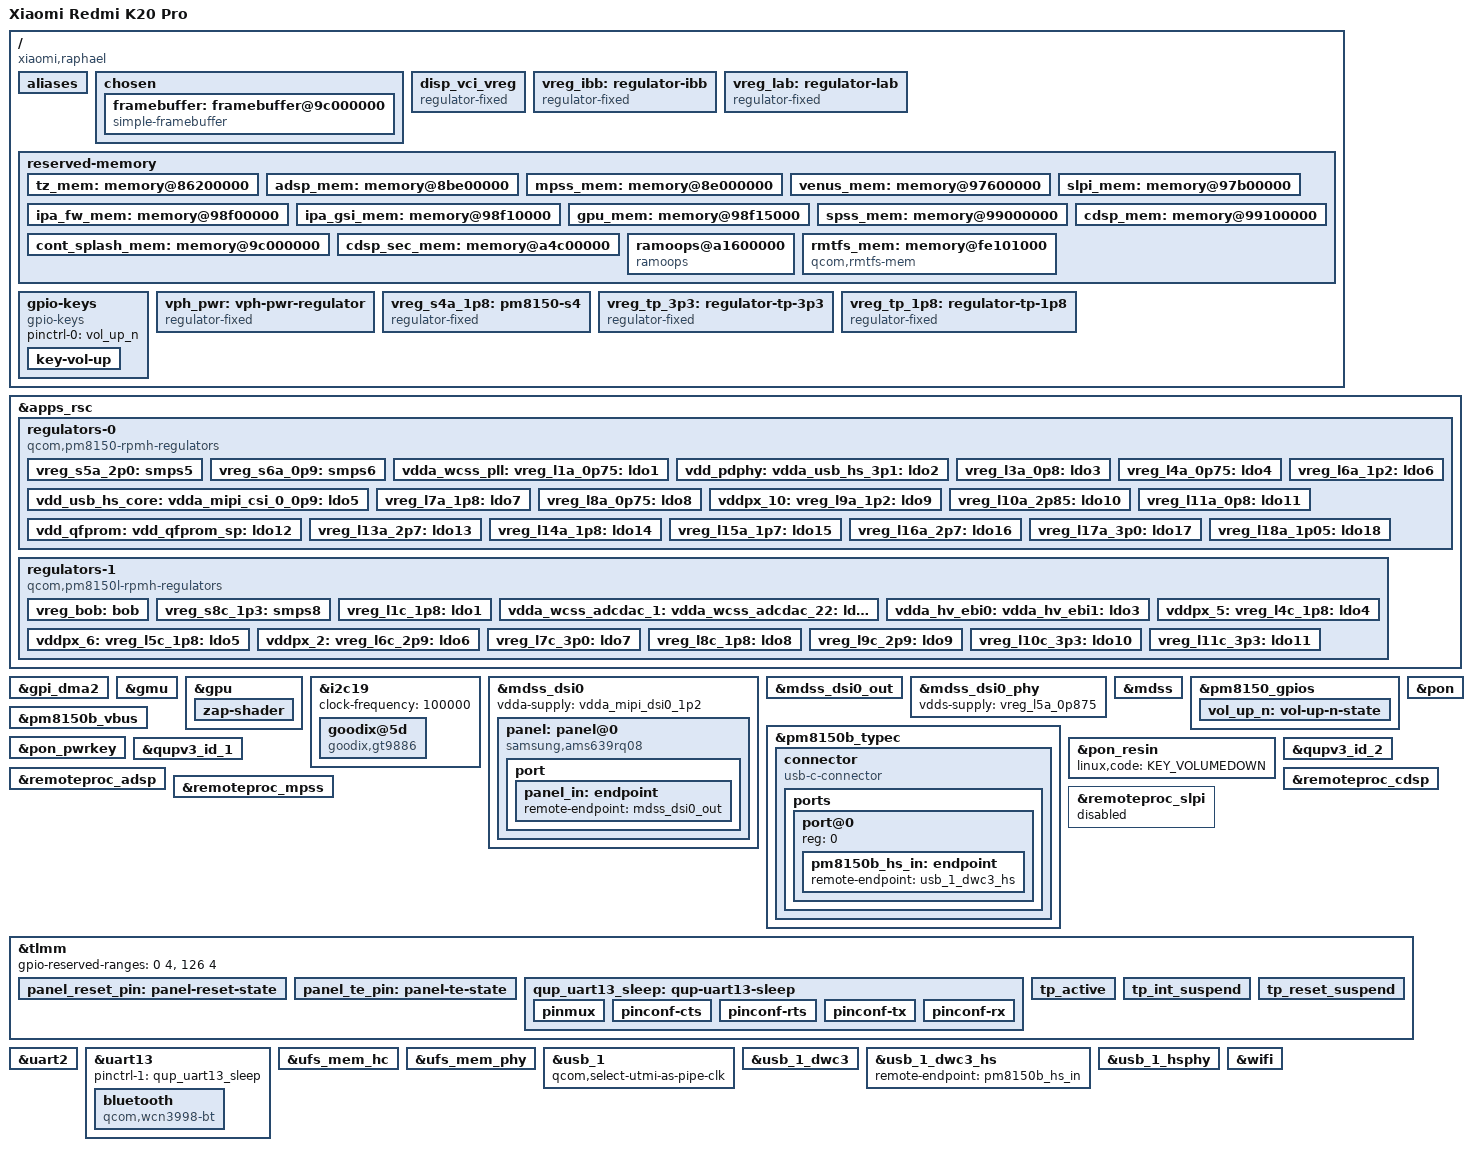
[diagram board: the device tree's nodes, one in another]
// SPDX-License-Identifier: BSD-3-Clause
/*
 * Copyright (c) 2025, Piyush Raj Chouhan <piyushchouhan1598@gmail.com>.
 */

/dts-v1/;

#include <dt-bindings/arm/qcom,ids.h>
#include <dt-bindings/pinctrl/qcom,pmic-gpio.h>
#include <dt-bindings/regulator/qcom,rpmh-regulator.h>
#include <dt-bindings/gpio/gpio.h>
#include <dt-bindings/usb/pd.h>
#include "sm8150.dtsi"
#include "pm8150.dtsi"
#include "pm8150b.dtsi"
#include "pm8150l.dtsi"

/* 
 * Rewrite reserved memory maps inherited from sm8150.dtsi to match the ones
 * used on xiaomi-raphael.
 * Note: this list is ordered by its memory address in sm8150.dtsi.
 */
/delete-node/ &tz_mem;      /* same address but larger, no place for rmtfs_mem! */
/delete-node/ &rmtfs_mem;   /* moved to completely different address */
/delete-node/ &adsp_mem;    /* same start address, but larger size */
/delete-node/ &mpss_mem;    /* same size, shifted higher, due to larger adsp_mem */
/delete-node/ &venus_mem;   /* same size, shifted higher */
/delete-node/ &slpi_mem;    /* same size, shifted higher */
/delete-node/ &ipa_fw_mem;  /* same size, shifted higher */
/delete-node/ &ipa_gsi_mem; /* same size, shifted higher */
/delete-node/ &gpu_mem;     /* same size, shifted higher */
/delete-node/ &spss_mem;    /* same size, shifted higher */
/delete-node/ &cdsp_mem;    /* same size, shifted higher */

/ {
	model = "Xiaomi Redmi K20 Pro";
	compatible = "xiaomi,raphael", "qcom,sm8150";
	qcom,msm-id = <QCOM_ID_SM8150 0x20000>; /* SM8150 v2 */
	qcom,board-id = <40 0>;
	chassis-type = "handset";

	aliases {
		bluetooth0 = &bluetooth;
		serial0 = &uart2;
		hsuart0 = &uart13;
		wifi0 = &wifi;
	};

	chosen {
		#address-cells = <2>;
		#size-cells = <2>;
		ranges;

		stdout-path = "serial0:115200n8";
		bootargs = "earlycon console=ttyMSM0,115200";

		framebuffer: framebuffer@9c000000 {
			compatible = "simple-framebuffer";
			reg = <0 0x9c000000 0 (1080 * 2340 * 4)>;
			width = <1080>;
			height = <2340>;
			stride = <(1080 * 4)>;
			format = "a8r8g8b8";
			display = <&panel>;
			clocks = <&gcc GCC_DISP_HF_AXI_CLK>;
		};
	};

	disp_vci_vreg: disp_vci_vreg {
		compatible = "regulator-fixed";
		regulator-name = "disp_vci_vreg";
		enable-active-high;
		regulator-boot-on;
		gpio = <&tlmm 99 GPIO_ACTIVE_HIGH>;
	};

	vreg_ibb: regulator-ibb {
		compatible = "regulator-fixed";
		regulator-name = "ibb";
		regulator-min-microvolt = <6000000>;
		regulator-max-microvolt = <6000000>;
	};

	vreg_lab: regulator-lab {
		compatible = "regulator-fixed";
		regulator-name = "lab";
		regulator-min-microvolt = <6000000>;
		regulator-max-microvolt = <6000000>;
	};

	reserved-memory {
		tz_mem: memory@86200000 {
			no-map;
			reg = <0x0 0x86200000 0x0 0x5500000>;
		};

		adsp_mem: memory@8be00000 {
			no-map;
			reg = <0x0 0x8be00000 0x0 0x2200000>;
		};

		mpss_mem: memory@8e000000 {
			no-map;
			reg = <0x0 0x8e000000 0x0 0x9600000>;
		};

		venus_mem: memory@97600000 {
			no-map;
			reg = <0x0 0x97600000 0x0 0x500000>;
		};

		slpi_mem: memory@97b00000 {
			no-map;
			reg = <0x0 0x97b00000 0x0 0x1400000>;
		};

		ipa_fw_mem: memory@98f00000 {
			no-map;
			reg = <0x0 0x98f00000 0x0 0x10000>;
		};

		ipa_gsi_mem: memory@98f10000 {
			no-map;
			reg = <0x0 0x98f10000 0x0 0x5000>;
		};

		gpu_mem: memory@98f15000 {
			no-map;
			reg = <0x0 0x98f15000 0x0 0x2000>;
		};

		spss_mem: memory@99000000 {
			no-map;
			reg = <0x0 0x99000000 0x0 0x100000>;
		};

		cdsp_mem: memory@99100000 {
			no-map;
			reg = <0x0 0x99100000 0x0 0x1400000>;
		};

		cont_splash_mem: memory@9c000000 {
			reg = <0x0 0x9c000000 0x0 0x2400000>;
			no-map;
		};

		cdsp_sec_mem: memory@a4c00000 {
			reg = <0x0 0xa4c00000 0x0 0x3c00000>;
			no-map;
		};
		
		ramoops@a1600000 {
			compatible = "ramoops";
			reg = <0x0 0xa1600000 0x0 0x800000>;
			console-size = <0x400000>;
			ecc-size = <0>;
			ftrace-size = <0>;
			pmsg-size = <0x200000>;
			record-size = <0>;
			no-map;
		};

		rmtfs_mem: memory@fe101000 {
			compatible = "qcom,rmtfs-mem";
			reg = <0 0xfe101000 0 0x300000>;
			no-map;

			qcom,client-id = <1>;
			qcom,vmid = <15>;
		};
	};

	gpio-keys {
		compatible = "gpio-keys";

		pinctrl-names = "default";
		pinctrl-0 = <&vol_up_n>;

		key-vol-up {
			label = "Volume Up";
			linux,code = <KEY_VOLUMEUP>;
			gpios = <&pm8150_gpios 6 GPIO_ACTIVE_LOW>;
		};
	};

	vph_pwr: vph-pwr-regulator {
		compatible = "regulator-fixed";
		regulator-name = "vph_pwr";
		regulator-min-microvolt = <3700000>;
		regulator-max-microvolt = <3700000>;
	};

	/*
	 * Apparently RPMh does not provide support for PM8150 S4 because it
	 * is always-on; model it as a fixed regulator.
	 */
	vreg_s4a_1p8: pm8150-s4 {
		compatible = "regulator-fixed";
		regulator-name = "vreg_s4a_1p8";

		regulator-min-microvolt = <1800000>;
		regulator-max-microvolt = <1800000>;

		regulator-always-on;
		regulator-boot-on;

		vin-supply = <&vph_pwr>;
	};

	vreg_tp_3p3: regulator-tp-3p3 {
		compatible = "regulator-fixed";
		regulator-name = "vreg_tp_3p3";
		regulator-min-microvolt = <3300000>;
		regulator-max-microvolt = <3300000>;
		gpio = <&tlmm 98 GPIO_ACTIVE_HIGH>;
		enable-active-high;
		regulator-boot-on;
		startup-delay-us = <5000>;
	};
	
	vreg_tp_1p8: regulator-tp-1p8 {
		compatible = "regulator-fixed";
		regulator-name = "vreg_tp_1p8";
		regulator-min-microvolt = <1800000>;
		regulator-max-microvolt = <1800000>;
		gpio = <&tlmm 100 GPIO_ACTIVE_HIGH>;
		enable-active-high;
		regulator-boot-on;
		startup-delay-us = <5000>;
	};
};

&apps_rsc {
	regulators-0 {
		compatible = "qcom,pm8150-rpmh-regulators";
		qcom,pmic-id = "a";

		vdd-s1-supply = <&vph_pwr>;
		vdd-s2-supply = <&vph_pwr>;
		vdd-s3-supply = <&vph_pwr>;
		vdd-s4-supply = <&vph_pwr>;
		vdd-s5-supply = <&vph_pwr>;
		vdd-s6-supply = <&vph_pwr>;
		vdd-s7-supply = <&vph_pwr>;
		vdd-s8-supply = <&vph_pwr>;
		vdd-s9-supply = <&vph_pwr>;
		vdd-s10-supply = <&vph_pwr>;

		vdd-l1-l8-l11-supply = <&vreg_s6a_0p9>;
		vdd-l2-l10-supply = <&vreg_bob>;
		vdd-l3-l4-l5-l18-supply = <&vreg_s6a_0p9>;
		vdd-l6-l9-supply = <&vreg_s8c_1p3>;
		vdd-l7-l12-l14-l15-supply = <&vreg_s5a_2p0>;
		vdd-l13-l16-l17-supply = <&vreg_bob>;

		vreg_s5a_2p0: smps5 {
			regulator-min-microvolt = <1904000>;
			regulator-max-microvolt = <2000000>;
		};

		vreg_s6a_0p9: smps6 {
			regulator-min-microvolt = <920000>;
			regulator-max-microvolt = <1128000>;
		};

		vdda_wcss_pll:
		vreg_l1a_0p75: ldo1 {
			regulator-min-microvolt = <752000>;
			regulator-max-microvolt = <752000>;
			regulator-initial-mode = <RPMH_REGULATOR_MODE_HPM>;
		};

		vdd_pdphy:
		vdda_usb_hs_3p1:
		vreg_l2a_3p1: ldo2 {
			regulator-min-microvolt = <3072000>;
			regulator-max-microvolt = <3072000>;
			regulator-initial-mode = <RPMH_REGULATOR_MODE_HPM>;
		};

		vreg_l3a_0p8: ldo3 {
			regulator-min-microvolt = <480000>;
			regulator-max-microvolt = <932000>;
			regulator-initial-mode = <RPMH_REGULATOR_MODE_HPM>;
		};

		/* L4A supplies VDD_LPI_MX_* (VDD_LPI_MX_A_1). Board label: vreg_l4a_0p75.
		* PM8150 device spec: L4A nominal = 0.816 V, active min = 0.752 V, active max = 0.904 V,
		* IRATED = 300 mA. If the board programs L4A to ~0.752 V, keep min=752000 and max=816000.
		*/
		vreg_l4a_0p75: ldo4 {
			regulator-min-microvolt = <752000>;
			regulator-max-microvolt = <816000>;
			regulator-initial-mode = <RPMH_REGULATOR_MODE_HPM>;
		};

		vdd_usb_hs_core:
		vdda_mipi_csi_0_0p9:
		vdda_mipi_csi_1_0p9:
		vdda_mipi_csi_2_0p9:
		vdda_mipi_csi_3_0p9:
		vdda_mipi_dsi_0_0p9:
		vdda_mipi_dsi_1_0p9:
		vdda_mipi_dsi_0_pll_0p9:
		vdda_mipi_dsi_1_pll_0p9:
		vdda_pcie_1ln_core:
		vdda_pcie_2ln_core:
		vdda_pll_hv_cc_ebi01:
		vdda_pll_hv_cc_ebi23:
		vdda_qrefs_0p875_5:
		vdda_sp_sensor:
		vdda_ufs_2ln_core_1:
		vdda_ufs_2ln_core_2:
		vdda_qlink_lv:
		vdda_qlink_lv_ck:
		vreg_l5a_0p875: ldo5 {
			regulator-min-microvolt = <880000>;
			regulator-max-microvolt = <880000>;
			regulator-initial-mode = <RPMH_REGULATOR_MODE_HPM>;
		};

		vreg_l6a_1p2: ldo6 {
			regulator-min-microvolt = <1200000>;
			regulator-max-microvolt = <1200000>;
			regulator-initial-mode = <RPMH_REGULATOR_MODE_HPM>;
		};

		vreg_l7a_1p8: ldo7 {
			regulator-min-microvolt = <1800000>;
			regulator-max-microvolt = <1800000>;
			regulator-initial-mode = <RPMH_REGULATOR_MODE_HPM>;
		};

		/* PM8150 LDO8 (L8A) — supplies vreg_l8a_0p75
		* Device spec: nominal 0.752 V, active min 0.752 V, active max 0.904 V, IRATED = 300 mA
		*/
		vreg_l8a_0p75: ldo8 {
                        regulator-min-microvolt = <752000>;                              
                        regulator-max-microvolt = <816000>;
		};

		vddpx_10:
		vreg_l9a_1p2: ldo9 {
			regulator-min-microvolt = <1200000>;
			regulator-max-microvolt = <1200000>;
			regulator-initial-mode = <RPMH_REGULATOR_MODE_HPM>;
		};

		vreg_l10a_2p85: ldo10 {
			regulator-min-microvolt = <2850000>;
			regulator-max-microvolt = <2960000>;
			regulator-initial-mode = <RPMH_REGULATOR_MODE_HPM>;
		};

		vreg_l11a_0p8: ldo11 {
			regulator-min-microvolt = <800000>;
			regulator-max-microvolt = <800000>;
			regulator-initial-mode = <RPMH_REGULATOR_MODE_HPM>;
		};

		vdd_qfprom:
		vdd_qfprom_sp:
		vdda_apc_cs_1p8:
		vdda_gfx_cs_1p8:
		vdda_usb_hs_1p8:
		vdda_qrefs_vref_1p8:
		vddpx_10_a:
		vreg_l12a_1p8: ldo12 {
			regulator-min-microvolt = <1800000>;
			regulator-max-microvolt = <1800000>;
			regulator-initial-mode = <RPMH_REGULATOR_MODE_HPM>;
		};

		vreg_l13a_2p7: ldo13 {
			regulator-min-microvolt = <2704000>;
			regulator-max-microvolt = <2704000>;
			regulator-initial-mode = <RPMH_REGULATOR_MODE_HPM>;
		};

		vreg_l14a_1p8: ldo14 {
			regulator-min-microvolt = <1800000>;
			regulator-max-microvolt = <1880000>;
			regulator-initial-mode = <RPMH_REGULATOR_MODE_HPM>;
		};

		vreg_l15a_1p7: ldo15 {
			regulator-min-microvolt = <1704000>;
			regulator-max-microvolt = <1704000>;
			regulator-initial-mode = <RPMH_REGULATOR_MODE_HPM>;
		};

		vreg_l16a_2p7: ldo16 {
			regulator-min-microvolt = <2704000>;
			regulator-max-microvolt = <2960000>;
			regulator-initial-mode = <RPMH_REGULATOR_MODE_HPM>;
		};

		vreg_l17a_3p0: ldo17 {
			regulator-min-microvolt = <2856000>;
			regulator-max-microvolt = <3008000>;
			regulator-initial-mode = <RPMH_REGULATOR_MODE_HPM>;
		};

		vreg_l18a_1p05: ldo18 {
			regulator-min-microvolt = <800000>;
			regulator-max-microvolt = <800000>;
			regulator-initial-mode = <RPMH_REGULATOR_MODE_HPM>;
		};
	};

	regulators-1 {
		compatible = "qcom,pm8150l-rpmh-regulators";
		qcom,pmic-id = "c";

		vdd-s1-supply = <&vph_pwr>;
		vdd-s2-supply = <&vph_pwr>;
		vdd-s3-supply = <&vph_pwr>;
		vdd-s4-supply = <&vph_pwr>;
		vdd-s5-supply = <&vph_pwr>;
		vdd-s6-supply = <&vph_pwr>;
		vdd-s7-supply = <&vph_pwr>;
		vdd-s8-supply = <&vph_pwr>;

		vdd-l1-l8-supply = <&vreg_s4a_1p8>;
		vdd-l2-l3-supply = <&vreg_s8c_1p3>;
		vdd-l4-l5-l6-supply = <&vreg_bob>;
		vdd-l7-l11-supply = <&vreg_bob>;
		vdd-l9-l10-supply = <&vreg_bob>;

		vdd-bob-supply = <&vph_pwr>;
		vdd-flash-supply = <&vreg_bob>;
		vdd-rgb-supply = <&vreg_bob>;

		vreg_bob: bob {
			regulator-min-microvolt = <3008000>;
			regulator-max-microvolt = <4000000>;
			regulator-initial-mode = <RPMH_REGULATOR_MODE_AUTO>;
			regulator-allow-bypass;
		};

		vreg_s8c_1p3: smps8 {
			regulator-min-microvolt = <1352000>;
			regulator-max-microvolt = <1352000>;
		};

		vreg_l1c_1p8: ldo1 {
			regulator-min-microvolt = <1800000>;
			regulator-max-microvolt = <1800000>;
			regulator-initial-mode = <RPMH_REGULATOR_MODE_HPM>;
		};

		vdda_wcss_adcdac_1:
		vdda_wcss_adcdac_22:
		vreg_l2c_1p3: ldo2 {
			regulator-min-microvolt = <1304000>;
			regulator-max-microvolt = <1304000>;
			regulator-initial-mode = <RPMH_REGULATOR_MODE_HPM>;
		};

		vdda_hv_ebi0:
		vdda_hv_ebi1:
		vdda_hv_ebi2:
		vdda_hv_ebi3:
		vdda_hv_refgen0:
		vdda_mipi_dsi0_1p2:
		vdda_qlink_hv_ck:
		vreg_l3c_1p2: ldo3 {
			regulator-min-microvolt = <1200000>;
			regulator-max-microvolt = <1200000>;
			regulator-initial-mode = <RPMH_REGULATOR_MODE_HPM>;
		};

		vddpx_5:
		vreg_l4c_1p8: ldo4 {
			regulator-min-microvolt = <1704000>;
			regulator-max-microvolt = <2928000>;
			regulator-initial-mode = <RPMH_REGULATOR_MODE_HPM>;
		};

		vddpx_6:
		vreg_l5c_1p8: ldo5 {
			regulator-min-microvolt = <1704000>;
			regulator-max-microvolt = <2928000>;
			regulator-initial-mode = <RPMH_REGULATOR_MODE_HPM>;
		};

		vddpx_2:
		vreg_l6c_2p9: ldo6 {
			regulator-min-microvolt = <1800000>;
			regulator-max-microvolt = <2960000>;
			regulator-initial-mode = <RPMH_REGULATOR_MODE_HPM>;
		};

		vreg_l7c_3p0: ldo7 {
			regulator-min-microvolt = <2856000>;
			regulator-max-microvolt = <3104000>;
			regulator-initial-mode = <RPMH_REGULATOR_MODE_HPM>;
		};

		vreg_l8c_1p8: ldo8 {
			regulator-min-microvolt = <1800000>;
			regulator-max-microvolt = <1800000>;
			regulator-initial-mode = <RPMH_REGULATOR_MODE_HPM>;
		};

		vreg_l9c_2p9: ldo9 {
			regulator-min-microvolt = <2704000>;
			regulator-max-microvolt = <2960000>;
			regulator-initial-mode = <RPMH_REGULATOR_MODE_HPM>;
		};

		vreg_l10c_3p3: ldo10 {
			regulator-min-microvolt = <3000000>;
			regulator-max-microvolt = <3312000>;
			regulator-initial-mode = <RPMH_REGULATOR_MODE_HPM>;
		};

		vreg_l11c_3p3: ldo11 {
			regulator-min-microvolt = <3000000>;
			regulator-max-microvolt = <3312000>;
			regulator-initial-mode = <RPMH_REGULATOR_MODE_HPM>;
		};
	};
};

&gpi_dma2 {
	status = "okay";
};

&gmu {
	status = "okay";
};

&gpu {
	status = "okay";
	
	zap-shader {
		memory-region = <&gpu_mem>;
		firmware-name = "qcom/sm8150/Xiaomi/raphael/a640_zap.mbn";
	};
};

&i2c19 {
	clock-frequency = <100000>;
	status = "okay";
	goodix@5d {
		compatible = "goodix,gt9886";
		reg = <0x5d>;
		avdd-supply = <&vreg_tp_3p3>;
		vddio-supply = <&vreg_tp_1p8>;
		interrupts-extended = <&tlmm 122 IRQ_TYPE_LEVEL_LOW>;
		reset-gpios = <&tlmm 54 GPIO_ACTIVE_LOW>;
		touchscreen-size-x = <1080>;
		touchscreen-size-y = <2340>;
	};
};

&mdss_dsi0 {
	vdda-supply = <&vdda_mipi_dsi0_1p2>;
	status = "okay";
	panel:	panel@0 {
		compatible = "samsung,ams639rq08";
		reg = <0>;
		status = "okay";
		
		vddio-supply = <&vreg_l14a_1p8>;
		vdd3p3-supply = <&disp_vci_vreg>;

		vsn-supply = <&vreg_ibb>;
		vsp-supply = <&vreg_lab>;

		reset-gpios = <&tlmm 6 GPIO_ACTIVE_LOW>;
		
		pinctrl-names = "default", "sleep";
		pinctrl-0 = <&panel_reset_pin &panel_te_pin>;

		port {
			panel_in: endpoint {
				remote-endpoint = <&mdss_dsi0_out>;
			};
		};
	};
};

&mdss_dsi0_out {
	data-lanes = <0 1 2 3>;
	remote-endpoint = <&panel_in>;
};

&mdss_dsi0_phy {
	status = "okay";
	vdds-supply = <&vreg_l5a_0p875>;
};

&mdss {
	status = "okay";
};

&pm8150_gpios {
	vol_up_n: vol-up-n-state {
		pins = "gpio6";
		function = PMIC_GPIO_FUNC_NORMAL;
		input-enable;
		bias-pull-up;
	};
};

&pm8150b_typec {
	vdd-vbus-supply = <&pm8150b_vbus>;
	vdd-pdphy-supply = <&vdda_usb_hs_3p1>;
	status = "okay";

	connector {
		compatible = "usb-c-connector";

		power-role = "source";
		data-role = "dual";
		self-powered;

		source-pdos = <PDO_FIXED(5000, 3000, PDO_FIXED_DUAL_ROLE |
			       PDO_FIXED_USB_COMM | PDO_FIXED_DATA_SWAP)>;

		ports {
			#address-cells = <1>;
			#size-cells = <0>;

			port@0 {
				reg = <0>;
				pm8150b_hs_in: endpoint {
					remote-endpoint = <&usb_1_dwc3_hs>;
				};
			};
		};
	};
};

&pm8150b_vbus {
	regulator-min-microamp = <500000>;
	regulator-max-microamp = <3000000>;
	status = "okay";
};

&pon {
	mode-bootloader = <0x2>;
	mode-recovery = <0x1>;
};

&pon_pwrkey {
	status = "okay";
};

&pon_resin {
	status = "okay";

	linux,code = <KEY_VOLUMEDOWN>;
};

&qupv3_id_1 {
	status = "okay";
};

&qupv3_id_2 {
	status = "okay";
};

&remoteproc_adsp {
	status = "okay";
	firmware-name = "qcom/sm8150/Xiaomi/raphael/adsp.mbn";
};

&remoteproc_cdsp {
	status = "okay";
	firmware-name = "qcom/sm8150/Xiaomi/raphael/cdsp.mbn";
};

&remoteproc_mpss {
	status = "okay";
	firmware-name = "qcom/sm8150/Xiaomi/raphael/modem.mbn";
};

&remoteproc_slpi {
	status = "disabled";
	firmware-name = "qcom/sm8150/Xiaomi/raphael/slpi.mbn";
};

&tlmm {
	/* gpios 0..3 are NFC spi, gpios 126..129 are FP spi */
	gpio-reserved-ranges = <0 4>, <126 4>;

	/* GPIOs for display panel */
	panel_reset_pin: panel-reset-state {
		pins = "gpio6";
		function = "gpio";
		drive-strength = <2>;
		bias-disable;
		output-low;
		power-source = <1>;
	};
	panel_te_pin: panel-te-state {
		pins = "gpio8";
		function = "mdp_vsync";
		drive-strength = <2>;
		bias-pull-down;
	};

	/* GPIOs for QUP UART */


	qup_uart13_sleep: qup-uart13-sleep {
		pinmux {
			pins = "gpio43", "gpio44",
			       "gpio45", "gpio46";
			function = "gpio";
		};
		pinconf-cts {
			/*
			 * Configure a pull-down on CTS to match the pull of
			 * the Bluetooth module.
			 */
			pins = "gpio43";
			bias-pull-down;
		};
		pinconf-rts {
			/*
			 * Configure pull-down on RTS. As RTS is active low
			 * signal, pull it low to indicate the BT SoC that it
			 * can wakeup the system anytime from suspend state by
			 * pulling RX low (by sending wakeup bytes).
			 */
			 pins = "gpio44";
			 bias-pull-down;
		};
		pinconf-tx {
			/*
			 * Configure pull-up on TX when it isn't actively driven
			 * to prevent BT SoC from receiving garbage during sleep.
			 */
			pins = "gpio45";
			bias-pull-up;
		};
		pinconf-rx {
			/*
			 * Configure a pull-up on RX. This is needed to avoid
			 * garbage data when the TX pin of the Bluetooth module
			 * is floating which may cause spurious wakeups.
			 */
			pins = "gpio46";
			bias-pull-up;
		};
	};

	/* GPIOs for touch panel */
	tp_active: tp_active {
			pins = "gpio122", "gpio54";
			function = "gpio";
			drive-strength = <16>;
			bias-pull-up;
	};
	
	tp_int_suspend: tp_int_suspend {
			pins = "gpio122";
			function = "gpio";
			drive-strength = <16>;
			input-enable;
			slew-rate = <0>;
			bias-pull-up;
	};

	tp_reset_suspend: tp_reset_suspend {
			pins = "gpio54";
			function = "gpio";
			drive-strength = <16>;
			slew-rate = <1>;
			bias-disable;
			output-high;
	};
};

&uart2 {
	status = "okay";
};

&uart13 {
	status = "okay";

	pinctrl-names = "default", "sleep";
	pinctrl-1 = <&qup_uart13_sleep>;

	bluetooth: bluetooth {
		compatible = "qcom,wcn3998-bt";
		vddio-supply = <&vreg_l7a_1p8>;
		vddxo-supply = <&vreg_l7a_1p8>;
		vddrf-supply = <&vreg_l2c_1p3>;
		vddch0-supply = <&vreg_l11c_3p3>;
		max-speed = <3200000>;
		firmware-name = "crnv21.bin", "crbtfw21.tlv";
	};
};

&ufs_mem_hc {
	status = "okay";

	reset-gpios = <&tlmm 175 GPIO_ACTIVE_LOW>;

	vcc-supply = <&vreg_l10a_2p85>;
	vcc-max-microamp = <750000>;
	vccq-supply = <&vreg_l9a_1p2>;
	vccq-max-microamp = <700000>;
	vccq2-supply = <&vreg_s4a_1p8>;
	vccq2-max-microamp = <750000>;
};

&ufs_mem_phy {
	status = "okay";

	vdda-phy-supply = <&vdda_ufs_2ln_core_1>;
	vdda-pll-supply = <&vreg_l3c_1p2>;
};

&usb_1 {
	qcom,select-utmi-as-pipe-clk;
	status = "okay";
};

&usb_1_dwc3 {
	dr_mode = "otg";
	usb-role-switch;
	maximum-speed = "high-speed";
	/* Remove USB3 phy */
	phys = <&usb_1_hsphy>;
	phy-names = "usb2-phy";
};

&usb_1_dwc3_hs {
	remote-endpoint = <&pm8150b_hs_in>;
};

&usb_1_hsphy {
	vdda-pll-supply = <&vdd_usb_hs_core>;
	vdda33-supply = <&vdda_usb_hs_3p1>;
	vdda18-supply = <&vdda_usb_hs_1p8>;
	status = "okay";
};

&wifi {
	status = "okay";

	vdd-0.8-cx-mx-supply = <&vdda_wcss_pll>;
	vdd-1.8-xo-supply = <&vreg_l7a_1p8>;
	vdd-1.3-rfa-supply = <&vdda_wcss_adcdac_1>;
	vdd-3.3-ch0-supply = <&vreg_l11c_3p3>;
	vdd-3.3-ch1-supply = <&vreg_l10c_3p3>;
	qcom,calibration-variant = "xiaomi_raphael";
};
